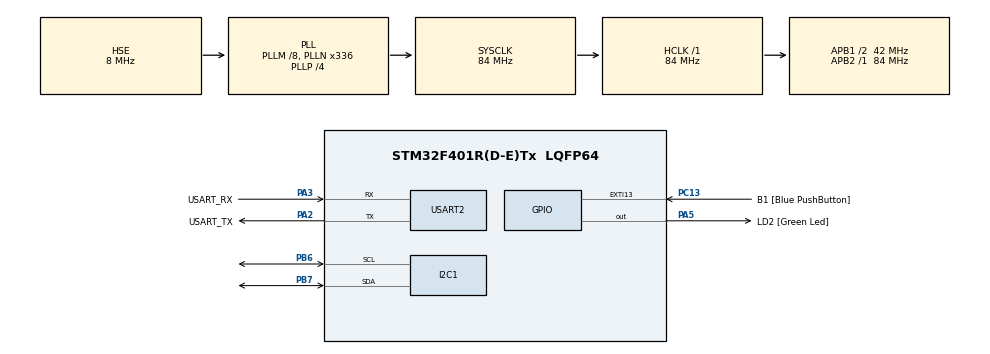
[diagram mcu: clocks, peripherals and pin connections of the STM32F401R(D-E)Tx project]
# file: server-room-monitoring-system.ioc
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FREERTOS.Tasks01=defaultTask,8,128,StartDefaultTask,Default,NULL,Dynamic,NULL,NULL
Mcu.Family=STM32F4
Mcu.Name=STM32F401R(D-E)Tx
Mcu.Package=LQFP64
NVIC.PriorityGroup=NVIC_PRIORITYGROUP_4
NVIC.TIM1_TRG_COM_TIM11_IRQn=true\:15\:0\:false\:false\:true\:false\:false\:true\:true
NVIC.TimeBase=TIM1_TRG_COM_TIM11_IRQn
NVIC.TimeBaseIP=TIM11
PA13.GPIO_Label=TMS
PA13.Mode=Serial_Wire
PA13.Signal=SYS_JTMS-SWDIO
PA14.GPIO_Label=TCK
PA14.Mode=Serial_Wire
PA14.Signal=SYS_JTCK-SWCLK
PA2.GPIO_Label=USART_TX
PA2.GPIO_Mode=GPIO_MODE_AF_PP
PA2.GPIO_PuPd=GPIO_NOPULL
PA2.GPIO_Speed=GPIO_SPEED_FREQ_LOW
PA2.Mode=Asynchronous
PA2.Signal=USART2_TX
PA3.GPIO_Label=USART_RX
PA3.GPIO_Mode=GPIO_MODE_AF_PP
PA3.GPIO_PuPd=GPIO_NOPULL
PA3.GPIO_Speed=GPIO_SPEED_FREQ_LOW
PA3.Mode=Asynchronous
PA3.Signal=USART2_RX
PA5.GPIO_Label=LD2 [Green Led]
PA5.GPIO_Mode=GPIO_MODE_OUTPUT_PP
PA5.GPIO_PuPd=GPIO_NOPULL
PA5.GPIO_Speed=GPIO_SPEED_FREQ_LOW
PA5.Signal=GPIO_Output
PB3.GPIO_Label=SWO
PB3.Signal=SYS_JTDO-SWO
PB6.Mode=I2C
PB6.Signal=I2C1_SCL
PB7.Mode=I2C
PB7.Signal=I2C1_SDA
PC13-ANTI_TAMP.GPIO_Label=B1 [Blue PushButton]
PC13-ANTI_TAMP.GPIO_ModeDefaultEXTI=GPIO_MODE_IT_FALLING
PC13-ANTI_TAMP.GPIO_PuPd=GPIO_NOPULL
PC13-ANTI_TAMP.Signal=GPXTI13
PC14-OSC32_IN.Signal=RCC_OSC32_IN
PC15-OSC32_OUT.Signal=RCC_OSC32_OUT
PH0\ -\ OSC_IN.Mode=HSE-External-Clock-Source
PH0\ -\ OSC_IN.Signal=RCC_OSC_IN
PH1\ -\ OSC_OUT.Mode=HSE-External-Clock-Source
PH1\ -\ OSC_OUT.Signal=RCC_OSC_OUT
ProjectManager.HeapSize=0x200
ProjectManager.StackSize=0x400
ProjectManager.TargetToolchain=CMake
RCC.48MHZClocksFreq_Value=48000000
RCC.AHBFreq_Value=84000000
RCC.APB1CLKDivider=RCC_HCLK_DIV2
RCC.APB1Freq_Value=42000000
RCC.APB1TimFreq_Value=84000000
RCC.APB2Freq_Value=84000000
RCC.APB2TimFreq_Value=84000000
RCC.CortexFreq_Value=84000000
RCC.EnbaleCSS=true
RCC.HCLKFreq_Value=84000000
RCC.HSE_VALUE=8000000
RCC.HSI_VALUE=16000000
RCC.PLLM=8
RCC.PLLN=336
RCC.PLLP=RCC_PLLP_DIV4
RCC.PLLQ=7
RCC.PLLSourceVirtual=RCC_PLLSOURCE_HSE
RCC.SYSCLKFreq_VALUE=84000000
RCC.SYSCLKSource=RCC_SYSCLKSOURCE_PLLCLK
RCC.VCOOutputFreq_Value=336000000
USART2.VirtualMode=VM_ASYNC
VP_FREERTOS_VS_CMSIS_V2.Mode=CMSIS_V2
VP_SYS_VS_tim11.Mode=TIM11
board=NUCLEO-F401RE

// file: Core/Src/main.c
/* USER CODE BEGIN Header */
/**
  ******************************************************************************
  * @file           : main.c
  * @brief          : Main program body
  ******************************************************************************
  * @attention
  *
  * Copyright (c) 2026 STMicroelectronics.
  * All rights reserved.
  *
  * This software is licensed under terms that can be found in the LICENSE file
  * in the root directory of this software component.
  * If no LICENSE file comes with this software, it is provided AS-IS.
  *
  ******************************************************************************
  */
/* USER CODE END Header */
#include "main.h"
#include "cmsis_os.h"
#include "i2c.h"
#include "usart.h"
#include "gpio.h"

/* USER CODE BEGIN Includes */
#include <string.h>
#include "bmp280.h"
#include "app_tasks.h"
/* USER CODE END Includes */

/* USER CODE BEGIN PV */
BMP280_CalibData bmp280_calib;
/* USER CODE END PV */

void SystemClock_Config(void);
void MX_FREERTOS_Init(void);

int main(void)
{

  /* MCU Configuration--------------------------------------------------------*/

  /* Reset of all peripherals, Initializes the Flash interface and the Systick. */
  HAL_Init();

  /* Configure the system clock */
  SystemClock_Config();

  /* Initialize all configured peripherals */
  MX_GPIO_Init();
  MX_USART2_UART_Init();
  MX_I2C1_Init();
  /* USER CODE BEGIN 2 */
  const char *boot_msg = "[BOOT] Server Room Monitor starting...\r\n";
  HAL_UART_Transmit(&huart2, (uint8_t *)boot_msg, strlen(boot_msg), HAL_MAX_DELAY);

  BMP280_Init(&hi2c1);
  BMP280_ReadCalibration(&hi2c1, &bmp280_calib);
  /* USER CODE END 2 */

  /* Init scheduler */
  osKernelInitialize();  /* Call init function for freertos objects (in cmsis_os2.c) */
  MX_FREERTOS_Init();

  /* Start scheduler */
  osKernelStart();

  /* We should never get here as control is now taken by the scheduler */

  /* Infinite loop */
  while (1)
  {

  }
}

void SystemClock_Config(void)
{
  RCC_OscInitTypeDef RCC_OscInitStruct = {0};
  RCC_ClkInitTypeDef RCC_ClkInitStruct = {0};

  /** Configure the main internal regulator output voltage
  */
  __HAL_RCC_PWR_CLK_ENABLE();
  __HAL_PWR_VOLTAGESCALING_CONFIG(PWR_REGULATOR_VOLTAGE_SCALE2);

  /** Initializes the RCC Oscillators according to the specified parameters
  * in the RCC_OscInitTypeDef structure.
  */
  RCC_OscInitStruct.OscillatorType = RCC_OSCILLATORTYPE_HSE;
  RCC_OscInitStruct.HSEState = RCC_HSE_BYPASS;
  RCC_OscInitStruct.PLL.PLLState = RCC_PLL_ON;
  RCC_OscInitStruct.PLL.PLLSource = RCC_PLLSOURCE_HSE;
  RCC_OscInitStruct.PLL.PLLM = 8;
  RCC_OscInitStruct.PLL.PLLN = 336;
  RCC_OscInitStruct.PLL.PLLP = RCC_PLLP_DIV4;
  RCC_OscInitStruct.PLL.PLLQ = 7;
  if (HAL_RCC_OscConfig(&RCC_OscInitStruct) != HAL_OK)
  {
    Error_Handler();
  }

  /** Initializes the CPU, AHB and APB buses clocks
  */
  RCC_ClkInitStruct.ClockType = RCC_CLOCKTYPE_HCLK|RCC_CLOCKTYPE_SYSCLK
                              |RCC_CLOCKTYPE_PCLK1|RCC_CLOCKTYPE_PCLK2;
  RCC_ClkInitStruct.SYSCLKSource = RCC_SYSCLKSOURCE_PLLCLK;
  RCC_ClkInitStruct.AHBCLKDivider = RCC_SYSCLK_DIV1;
  RCC_ClkInitStruct.APB1CLKDivider = RCC_HCLK_DIV2;
  RCC_ClkInitStruct.APB2CLKDivider = RCC_HCLK_DIV1;

  if (HAL_RCC_ClockConfig(&RCC_ClkInitStruct, FLASH_LATENCY_2) != HAL_OK)
  {
    Error_Handler();
  }

  /** Enables the Clock Security System
  */
  HAL_RCC_EnableCSS();
}

void HAL_TIM_PeriodElapsedCallback(TIM_HandleTypeDef *htim)
{
  if (htim->Instance == TIM11)
  {
    HAL_IncTick();
  }
}

void Error_Handler(void)
{
  __disable_irq();
  while (1)
  {
  }
}

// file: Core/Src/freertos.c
/* USER CODE BEGIN Header */
/**
  ******************************************************************************
  * File Name          : freertos.c
  * Description        : Code for freertos applications
  ******************************************************************************
  * @attention
  *
  * Copyright (c) 2026 STMicroelectronics.
  * All rights reserved.
  *
  * This software is licensed under terms that can be found in the LICENSE file
  * in the root directory of this software component.
  * If no LICENSE file comes with this software, it is provided AS-IS.
  *
  ******************************************************************************
  */
/* USER CODE END Header */

#include "FreeRTOS.h"
#include "task.h"
#include "main.h"
#include "cmsis_os.h"

/* USER CODE BEGIN Includes */
#include "app_tasks.h"
/* USER CODE END Includes */

/* USER CODE BEGIN Variables */
osMessageQueueId_t temp_queue;
/* USER CODE END Variables */
/* Definitions for defaultTask */
osThreadId_t defaultTaskHandle;
const osThreadAttr_t defaultTask_attributes = {
  .name = "defaultTask",
  .stack_size = 128 * 4,
  .priority = (osPriority_t) osPriorityLow,
};

void StartDefaultTask(void *argument);

void MX_FREERTOS_Init(void); /* (MISRA C 2004 rule 8.1) */

void MX_FREERTOS_Init(void) {

  /* USER CODE BEGIN RTOS_QUEUES */
  /* add queues, ... */
  temp_queue = osMessageQueueNew(4, sizeof(int32_t), NULL);
  /* USER CODE END RTOS_QUEUES */

  /* Create the thread(s) */
  /* creation of defaultTask */
  defaultTaskHandle = osThreadNew(StartDefaultTask, NULL, &defaultTask_attributes);

  /* USER CODE BEGIN RTOS_THREADS */
  /* add threads, ... */
  osThreadNew(SensorTask, NULL, &(osThreadAttr_t){ .name = "SensorTask", .stack_size = 256 * 4, .priority = osPriorityNormal });
  osThreadNew(LoggerTask, NULL, &(osThreadAttr_t){ .name = "LoggerTask", .stack_size = 256 * 4, .priority = osPriorityNormal });
  /* USER CODE END RTOS_THREADS */

}

void StartDefaultTask(void *argument)
{
  for(;;)
  {
    osDelay(1);
  }
}
